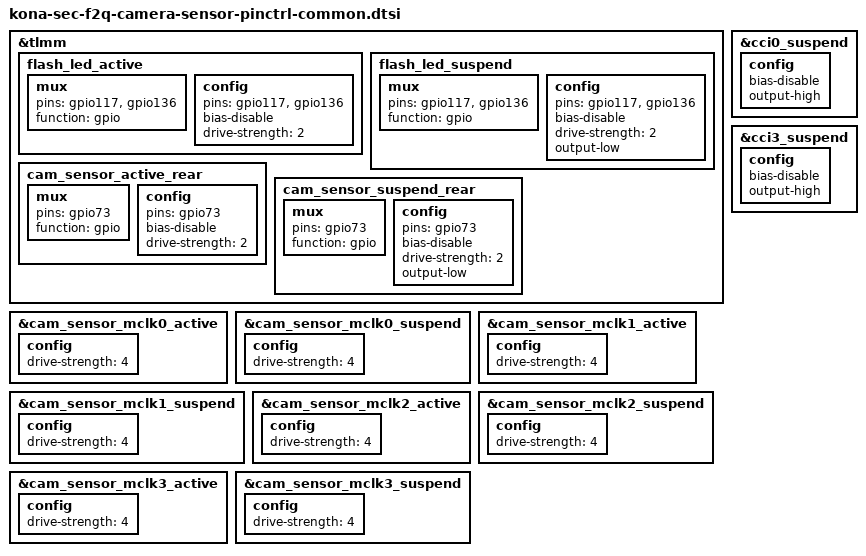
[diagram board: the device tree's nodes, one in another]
/* Copyright (c) 2019, The Linux Foundation. All rights reserved.
 *
 * This program is free software; you can redistribute it and/or modify
 * it under the terms of the GNU General Public License version 2 and
 * only version 2 as published by the Free Software Foundation.
 *
 * This program is distributed in the hope that it will be useful,
 * but WITHOUT ANY WARRANTY; without even the implied warranty of
 * MERCHANTABILITY or FITNESS FOR A PARTICULAR PURPOSE.  See the
 * GNU General Public License for more details.
 */

&tlmm {
	flash_led_active: flash_led_active {
		mux {
			pins = "gpio117","gpio136";
			function = "gpio";
		};

		config {
			pins = "gpio117","gpio136";
			bias-disable; /* No PULL */
			drive-strength = <2>; /* 2 MA */
		};
	};

	flash_led_suspend: flash_led_suspend {
		mux {
			pins = "gpio117","gpio136";
			function = "gpio";
		};

		config {
			pins = "gpio117","gpio136";
			bias-disable; /* No PULL */
			drive-strength = <2>; /* 2 MA */
			output-low;
		};
	};

	cam_sensor_active_rear: cam_sensor_active_rear {
		mux {
			pins = "gpio73";
			function = "gpio";
		};

		config {
			pins = "gpio73";
			bias-disable; /* No PULL */
			drive-strength = <2>; /* 2 MA */
		};
	};

	cam_sensor_suspend_rear: cam_sensor_suspend_rear {
		mux {
			pins = "gpio73";
			function = "gpio";
		};

		config {
			pins = "gpio73";
			bias-disable; /* No PULL */
			drive-strength = <2>; /* 2 MA */
			output-low;
		};
	};
};

&cci0_suspend {
	config {
		bias-disable; /* No PULL */
		output-high;
	};
};

&cci3_suspend {
	config {
		bias-disable; /* No PULL */
		output-high;
	};
};

&cam_sensor_mclk0_active {
	config {
		drive-strength = <4>; /* 4 MA */
	};
};

&cam_sensor_mclk0_suspend {
	config {
		drive-strength = <4>; /* 4 MA */
	};
};

&cam_sensor_mclk1_active {
	config {
		drive-strength = <4>; /* 4 MA */
	};
};

&cam_sensor_mclk1_suspend {
	config {
		drive-strength = <4>; /* 4 MA */
	};
};

&cam_sensor_mclk2_active {
	config {
		drive-strength = <4>; /* 4 MA */
	};
};

&cam_sensor_mclk2_suspend {
	config {
		drive-strength = <4>; /* 4 MA */
	};
};

&cam_sensor_mclk3_active {
	config {
		drive-strength = <4>; /* 4 MA */
	};
};

&cam_sensor_mclk3_suspend {
	config {
		drive-strength = <4>; /* 4 MA */
	};
};

